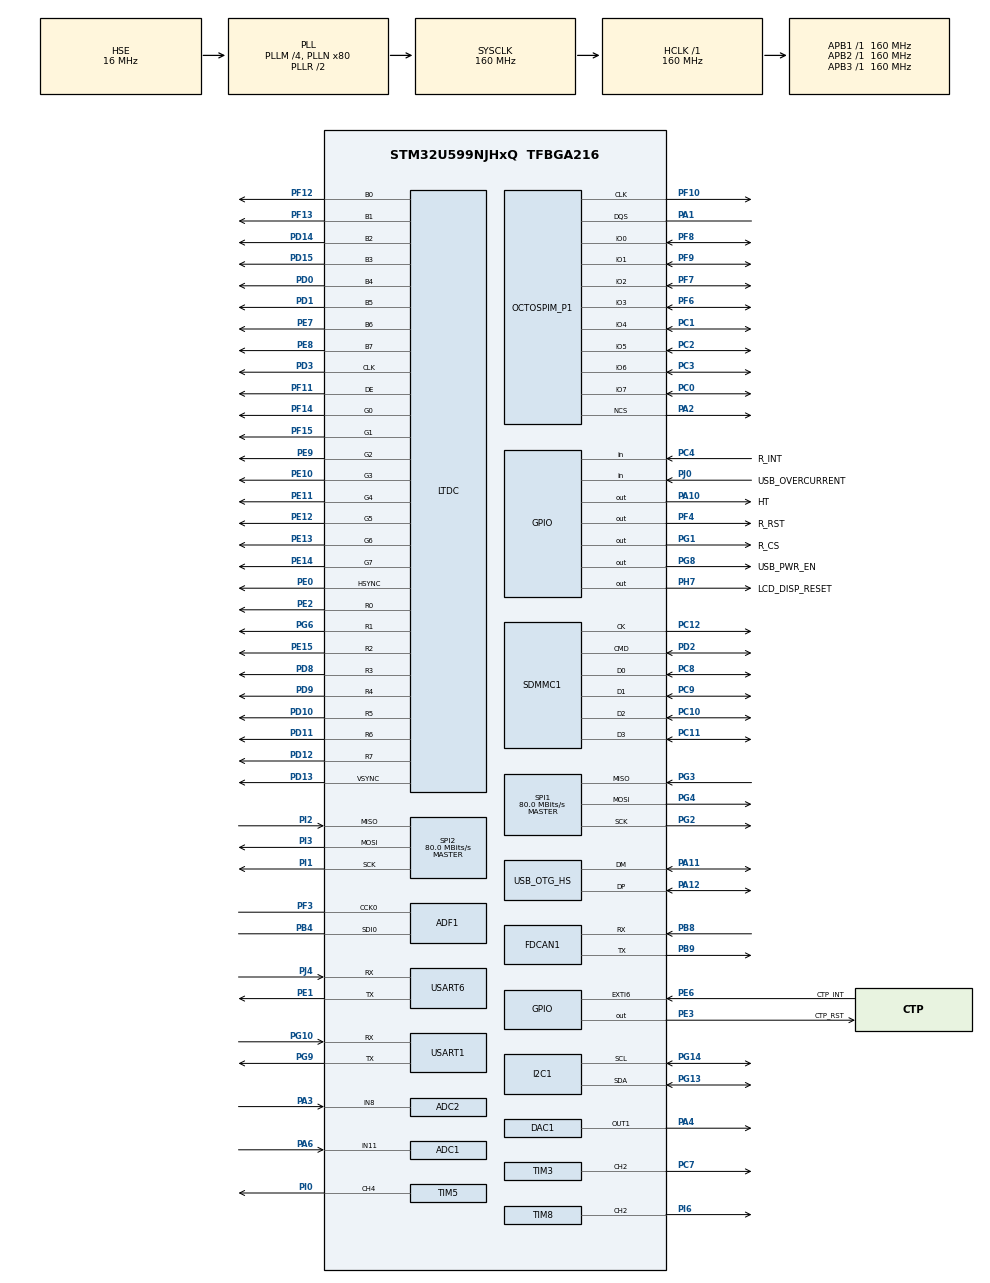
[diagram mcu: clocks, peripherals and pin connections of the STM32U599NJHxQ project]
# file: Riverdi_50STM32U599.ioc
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ADC1.Channel-0\#ChannelRegularConversion=ADC_CHANNEL_11
ADC1.ClockPrescaler=ADC_CLOCK_ASYNC_DIV4
ADC1.ContinuousConvMode=ENABLE
ADC1.ConversionDataManagement=ADC_CONVERSIONDATA_DMA_CIRCULAR
ADC1.DMAContinuousRequests=ENABLE
ADC1.DataAlign=ADC_DATAALIGN_LEFT
ADC1.MonitoredBy-0\#ChannelRegularConversion=__NULL
ADC1.NbrOfConversionFlag=1
ADC1.OffsetNumber-0\#ChannelRegularConversion=ADC_OFFSET_NONE
ADC1.Rank-0\#ChannelRegularConversion=1
ADC1.SamplingTime-0\#ChannelRegularConversion=ADC_SAMPLETIME_5CYCLE
ADC1.master=1
ADC2.Channel-0\#ChannelRegularConversion=ADC_CHANNEL_8
ADC2.ClockPrescaler=ADC_CLOCK_ASYNC_DIV4
ADC2.ContinuousConvMode=ENABLE
ADC2.ConversionDataManagement=ADC_CONVERSIONDATA_DMA_CIRCULAR
ADC2.DMAContinuousRequests=ENABLE
ADC2.DataAlign=ADC_DATAALIGN_RIGHT
ADC2.MonitoredBy-0\#ChannelRegularConversion=__NULL
ADC2.NbrOfConversionFlag=1
ADC2.OffsetNumber-0\#ChannelRegularConversion=ADC_OFFSET_NONE
ADC2.Rank-0\#ChannelRegularConversion=1
ADC2.SamplingTime-0\#ChannelRegularConversion=ADC_SAMPLETIME_5CYCLE
ADC2.TriggerFrequencyMode=ADC_TRIGGER_FREQ_LOW
CORTEX_M33_NS.userName=CORTEX_M33
DAC1.DAC_Channel-DAC_OUT1=DAC_CHANNEL_1
DAC1.DAC_OutputBuffer_OUT1-DAC_OUT1=DAC_OUTPUTBUFFER_ENABLE
DAC1.DAC_SignedFormat-DAC_OUT1=ENABLE
DAC1.DAC_Trigger-DAC_OUT1=DAC_TRIGGER_T1_TRGO
DAC1.WaveGeneration-DAC_OUT1=DISABLE
FDCAN1.CalculateBaudRateNominal=3333333
FDCAN1.CalculateTimeBitNominal=300
FDCAN1.CalculateTimeQuantumNominal=100.0
FDCAN1.FrameFormat=FDCAN_FRAME_FD_BRS
FILEX.FILEX_APPLICATION_THREAD_STACK_SIZE=4096
FILEX.FX_APP_MEM_POOL_SIZE=64*1024
FILEX.FX_DRIVER_SDMMC_INIT=1
FILEX.FX_DRIVER_USE_64BIT_LBA=0
FILEX.FX_ENABLE_EXFAT=1
FILEX.FX_EXFAT_MAX_CACHE_SIZE_NB_BIT=9
FILEX.FX_FAT_MAP_SIZE=256
FILEX.FX_FAULT_TOLERANT_CACHE_SIZE_NB_SIZE=9
FILEX.FX_MEDIA_STATISTICS_DISABLE=0
FILEX.FX_SD_INTERFACE=1
FILEX.FX_UPDATE_RATE_IN_SECONDS=1
FILEX.MAX_FAT_CACHE_NB_BIT=4
FILEX.MAX_SECTOR_CACHE_NB_BIT=4
FILEX.useRTOS=1
GPDMA1.CIRCULARMODE_GPDMACH0=ENABLE
GPDMA1.CIRCULARMODE_GPDMACH1=ENABLE
GPDMA1.CIRCULARMODE_GPDMACH2=ENABLE
GPDMA1.DATAHANDLING_GPDMACH1=NONE
GPDMA1.DATAHANDLING_GPDMACH2=NONE
GPDMA1.DESTDATAWIDTH_GPDMACH0=DMA_DEST_DATAWIDTH_HALFWORD
GPDMA1.DESTDATAWIDTH_GPDMACH1=DMA_DEST_DATAWIDTH_HALFWORD
GPDMA1.DESTDATAWIDTH_GPDMACH2=DMA_DEST_DATAWIDTH_HALFWORD
GPDMA1.DESTINC_GPDMACH1=DMA_DINC_INCREMENTED
GPDMA1.DIRECTION_GPDMACH2=DMA_MEMORY_TO_PERIPH
GPDMA1.IPHANDLE_GPDMACH0-SIMPLEREQUEST_GPDMACH0=__NULL
GPDMA1.IPHANDLE_GPDMACH1-SIMPLEREQUEST_GPDMACH1=__NULL
GPDMA1.IPHANDLE_GPDMACH2-SIMPLEREQUEST_GPDMACH2=__NULL
GPDMA1.REQUEST_GPDMACH0=GPDMA1_REQUEST_ADC1
GPDMA1.REQUEST_GPDMACH1=GPDMA1_REQUEST_ADC2
GPDMA1.REQUEST_GPDMACH2=GPDMA1_REQUEST_DAC1_CH1
GPDMA1.SRCDATAWIDTH_GPDMACH0=DMA_SRC_DATAWIDTH_HALFWORD
GPDMA1.SRCDATAWIDTH_GPDMACH1=DMA_SRC_DATAWIDTH_HALFWORD
GPDMA1.SRCDATAWIDTH_GPDMACH2=DMA_SRC_DATAWIDTH_HALFWORD
GPDMA1.SRCINC_GPDMACH2=DMA_SINC_INCREMENTED
GPDMA1.TRIGGERPOLARITY_GPDMACH1=DMA_TRIG_POLARITY_MASKED
I2C1.Timing=0x30909DEC
LTDC.ActiveW=800
LTDC.Alpha_L0=255
LTDC.FBStartAdress_L0=0x20156C00
LTDC.HBP=8
LTDC.HFP=8
LTDC.HSync=4
LTDC.ImageHeight_L0=480
LTDC.ImageWidth_L0=800
LTDC.Layers=0
LTDC.PixelFormat_L0=LTDC_PIXEL_FORMAT_RGB888
LTDC.VBP=8
LTDC.VFP=8
LTDC.WindowX1_L0=800
LTDC.WindowY1_L0=480
Mcu.Family=STM32U5
Mcu.Name=STM32U599NJHxQ
Mcu.Package=TFBGA216
NVIC.ADC1_2_IRQn=true\:0\:0\:false\:false\:true\:false\:true\:true\:true
NVIC.DAC1_IRQn=true\:0\:0\:false\:false\:true\:false\:true\:true\:true
NVIC.EXTI6_IRQn=true\:0\:0\:false\:false\:true\:false\:true\:true\:true
NVIC.GPDMA1_Channel0_IRQn=true\:0\:0\:false\:false\:true\:true\:false\:true\:true
NVIC.GPDMA1_Channel1_IRQn=true\:0\:0\:false\:false\:true\:true\:false\:true\:true
NVIC.GPDMA1_Channel2_IRQn=true\:0\:0\:false\:false\:true\:true\:false\:true\:true
NVIC.GPU2D_ER_IRQn=true\:0\:0\:false\:false\:true\:false\:false\:true\:true
NVIC.GPU2D_IRQn=true\:0\:0\:false\:false\:true\:false\:false\:true\:true
NVIC.LTDC_IRQn=true\:0\:0\:false\:false\:true\:false\:true\:true\:true
NVIC.OTG_HS_IRQn=true\:6\:0\:true\:false\:true\:false\:true\:true\:true
NVIC.PriorityGroup=NVIC_PRIORITYGROUP_4
NVIC.SDMMC1_IRQn=true\:0\:0\:false\:false\:true\:false\:true\:true\:true
NVIC.TIM2_IRQn=true\:15\:0\:false\:false\:true\:false\:false\:true\:true
NVIC.TimeBase=TIM2_IRQn
NVIC.TimeBaseIP=TIM2
OCTOSPI1.ChipSelectHighTime=2
OCTOSPI1.ClockPrescaler=2
OCTOSPI1.DelayHoldQuarterCycle=HAL_OSPI_DHQC_ENABLE
OCTOSPI1.FifoThreshold=4
OCTOSPI1.MemoryType=HAL_OSPI_MEMTYPE_MACRONIX
PA0.Signal=USART2_CTS
PA1.Mode=OCTOSPI1_Port1_DQS
PA1.Signal=OCTOSPIM_P1_DQS
PA10.GPIO_Label=HT
PA10.Signal=GPIO_Output
PA11.Mode=Internal_Phy_Host
PA11.Signal=USB_OTG_HS_DM
PA12.Mode=Internal_Phy_Host
PA12.Signal=USB_OTG_HS_DP
PA13\ (JTMS/SWDIO).Mode=Trace_Asynchronous_SW
PA13\ (JTMS/SWDIO).Signal=DEBUG_JTMS-SWDIO
PA14\ (JTCK/SWCLK).Mode=Trace_Asynchronous_SW
PA14\ (JTCK/SWCLK).Signal=DEBUG_JTCK-SWCLK
PA2.Mode=OCTOSPI1_Port1_NCS
PA2.Signal=OCTOSPIM_P1_NCS
PA3.Mode=IN8-Single-Ended
PA3.Signal=ADC2_IN8
PA4.Signal=COMP_DAC11_group
PA6.Mode=IN11-Single-Ended
PA6.Signal=ADC1_IN11
PB11.GPIO_Speed=GPIO_SPEED_FREQ_VERY_HIGH
PB11.Signal=I2C4_SDA
PB3\ (JTDO/TRACESWO).Mode=Trace_Asynchronous_SW
PB3\ (JTDO/TRACESWO).Signal=DEBUG_JTDO-SWO
PB4\ (NJTRST).Mode=MOD_ADF_CCK
PB4\ (NJTRST).Signal=ADF1_SDI0
PB8.GPIO_Speed=GPIO_SPEED_FREQ_VERY_HIGH
PB8.Mode=FDCAN_Activate
PB8.Signal=FDCAN1_RX
PB9.GPIO_Speed=GPIO_SPEED_FREQ_VERY_HIGH
PB9.Mode=FDCAN_Activate
PB9.Signal=FDCAN1_TX
PC0.Mode=OCTOSPI1_IOH_Port1H
PC0.Signal=OCTOSPIM_P1_IO7
PC1.Mode=OCTOSPI1_IOH_Port1H
PC1.Signal=OCTOSPIM_P1_IO4
PC10.GPIO_Speed_High_Only=GPIO_SPEED_FREQ_VERY_HIGH
PC10.Mode=SD_4_bits_Wide_bus
PC10.Signal=SDMMC1_D2
PC11.GPIO_Speed_High_Only=GPIO_SPEED_FREQ_VERY_HIGH
PC11.Mode=SD_4_bits_Wide_bus
PC11.Signal=SDMMC1_D3
PC12.GPIO_Speed_High_Only=GPIO_SPEED_FREQ_VERY_HIGH
PC12.Mode=SD_4_bits_Wide_bus
PC12.Signal=SDMMC1_CK
PC13.Signal=RTC_OUT1
PC14-OSC32_IN\ (PC14).Mode=LSE-External-Oscillator
PC14-OSC32_IN\ (PC14).Signal=RCC_OSC32_IN
PC15-OSC32_OUT\ (PC15).Mode=LSE-External-Oscillator
PC15-OSC32_OUT\ (PC15).Signal=RCC_OSC32_OUT
PC2.Mode=OCTOSPI1_IOH_Port1H
PC2.Signal=OCTOSPIM_P1_IO5
PC3.Mode=OCTOSPI1_IOH_Port1H
PC3.Signal=OCTOSPIM_P1_IO6
PC4.GPIO_Label=R_INT
PC4.Signal=GPIO_Input
PC5.Signal=USART3_RX
PC7.Signal=S_TIM3_CH2
PC8.GPIO_Speed_High_Only=GPIO_SPEED_FREQ_VERY_HIGH
PC8.Mode=SD_4_bits_Wide_bus
PC8.Signal=SDMMC1_D0
PC9.GPIO_Speed_High_Only=GPIO_SPEED_FREQ_VERY_HIGH
PC9.Mode=SD_4_bits_Wide_bus
PC9.Signal=SDMMC1_D1
PD0.GPIO_Speed=GPIO_SPEED_FREQ_VERY_HIGH
PD0.Mode=RGB888
PD0.Signal=LTDC_B4
PD1.GPIO_Speed=GPIO_SPEED_FREQ_VERY_HIGH
PD1.Mode=RGB888
PD1.Signal=LTDC_B5
PD10.GPIO_Speed=GPIO_SPEED_FREQ_VERY_HIGH
PD10.Mode=RGB888
PD10.Signal=LTDC_R5
PD11.GPIO_Speed=GPIO_SPEED_FREQ_VERY_HIGH
PD11.Mode=RGB888
PD11.Signal=LTDC_R6
PD12.GPIO_Speed=GPIO_SPEED_FREQ_VERY_HIGH
PD12.Mode=RGB888
PD12.Signal=LTDC_R7
PD13.GPIO_Speed=GPIO_SPEED_FREQ_VERY_HIGH
PD13.Mode=RGB888
PD13.Signal=LTDC_VSYNC
PD14.GPIO_Speed=GPIO_SPEED_FREQ_VERY_HIGH
PD14.Mode=RGB888
PD14.Signal=LTDC_B2
PD15.GPIO_Speed=GPIO_SPEED_FREQ_VERY_HIGH
PD15.Mode=RGB888
PD15.Signal=LTDC_B3
PD2.GPIO_Speed_High_Only=GPIO_SPEED_FREQ_VERY_HIGH
PD2.Mode=SD_4_bits_Wide_bus
PD2.Signal=SDMMC1_CMD
PD3.GPIO_Speed=GPIO_SPEED_FREQ_VERY_HIGH
PD3.Mode=RGB888
PD3.Signal=LTDC_CLK
PD4.Signal=USART2_RTS
PD5.Signal=USART2_TX
PD8.GPIO_Speed=GPIO_SPEED_FREQ_VERY_HIGH
PD8.Mode=RGB888
PD8.Signal=LTDC_R3
PD9.GPIO_Speed=GPIO_SPEED_FREQ_VERY_HIGH
PD9.Mode=RGB888
PD9.Signal=LTDC_R4
PE0.GPIO_Speed=GPIO_SPEED_FREQ_VERY_HIGH
PE0.Mode=RGB888
PE0.Signal=LTDC_HSYNC
PE1.Mode=Asynchronous
PE1.Signal=USART6_TX
PE10.GPIO_Speed=GPIO_SPEED_FREQ_VERY_HIGH
PE10.Mode=RGB888
PE10.Signal=LTDC_G3
PE11.GPIO_Speed=GPIO_SPEED_FREQ_VERY_HIGH
PE11.Mode=RGB888
PE11.Signal=LTDC_G4
PE12.GPIO_Speed=GPIO_SPEED_FREQ_VERY_HIGH
PE12.Mode=RGB888
PE12.Signal=LTDC_G5
PE13.GPIO_Speed=GPIO_SPEED_FREQ_VERY_HIGH
PE13.Mode=RGB888
PE13.Signal=LTDC_G6
PE14.GPIO_Speed=GPIO_SPEED_FREQ_VERY_HIGH
PE14.Mode=RGB888
PE14.Signal=LTDC_G7
PE15.GPIO_Speed=GPIO_SPEED_FREQ_VERY_HIGH
PE15.Mode=RGB888
PE15.Signal=LTDC_R2
PE2.GPIO_Speed=GPIO_SPEED_FREQ_VERY_HIGH
PE2.Mode=RGB888
PE2.Signal=LTDC_R0
PE3.GPIO_Label=CTP_RST
PE3.GPIO_PuPd=GPIO_PULLDOWN
PE3.Signal=GPIO_Output
PE6.GPIO_Label=CTP_INT
PE6.GPIO_ModeDefaultEXTI=GPIO_MODE_IT_FALLING
PE6.GPIO_PuPd=GPIO_PULLUP
PE6.Signal=GPXTI6
PE7.GPIO_Speed=GPIO_SPEED_FREQ_VERY_HIGH
PE7.Mode=RGB888
PE7.Signal=LTDC_B6
PE8.GPIO_Speed=GPIO_SPEED_FREQ_VERY_HIGH
PE8.Mode=RGB888
PE8.Signal=LTDC_B7
PE9.GPIO_Speed=GPIO_SPEED_FREQ_VERY_HIGH
PE9.Mode=RGB888
PE9.Signal=LTDC_G2
PF10.Mode=O1_P1_CLK
PF10.Signal=OCTOSPIM_P1_CLK
PF11.GPIO_Speed=GPIO_SPEED_FREQ_VERY_HIGH
PF11.Mode=RGB888
PF11.Signal=LTDC_DE
PF12.GPIO_Speed=GPIO_SPEED_FREQ_VERY_HIGH
PF12.Mode=RGB888
PF12.Signal=LTDC_B0
PF13.GPIO_Speed=GPIO_SPEED_FREQ_VERY_HIGH
PF13.Mode=RGB888
PF13.Signal=LTDC_B1
PF14.GPIO_Speed=GPIO_SPEED_FREQ_VERY_HIGH
PF14.Mode=RGB888
PF14.Signal=LTDC_G0
PF15.GPIO_Speed=GPIO_SPEED_FREQ_VERY_HIGH
PF15.Mode=RGB888
PF15.Signal=LTDC_G1
PF3.Mode=MOD_MDF_CCK0
PF3.Signal=ADF1_CCK0
PF4.GPIO_Label=R_RST
PF4.GPIO_PuPd=GPIO_PULLDOWN
PF4.Signal=GPIO_Output
PF6.Mode=OCTOSPI1_IOL_Port1L
PF6.Signal=OCTOSPIM_P1_IO3
PF7.Mode=OCTOSPI1_IOL_Port1L
PF7.Signal=OCTOSPIM_P1_IO2
PF8.Mode=OCTOSPI1_IOL_Port1L
PF8.Signal=OCTOSPIM_P1_IO0
PF9.Mode=OCTOSPI1_IOL_Port1L
PF9.Signal=OCTOSPIM_P1_IO1
PG1.GPIO_Label=R_CS
PG1.Signal=GPIO_Output
PG10.Mode=Asynchronous
PG10.Signal=USART1_RX
PG13.GPIO_Speed=GPIO_SPEED_FREQ_VERY_HIGH
PG13.Mode=I2C
PG13.Signal=I2C1_SDA
PG14.GPIO_Speed=GPIO_SPEED_FREQ_VERY_HIGH
PG14.Mode=I2C
PG14.Signal=I2C1_SCL
PG2.GPIO_Speed=GPIO_SPEED_FREQ_VERY_HIGH
PG2.Mode=Full_Duplex_Master
PG2.Signal=SPI1_SCK
PG3.GPIO_Speed=GPIO_SPEED_FREQ_VERY_HIGH
PG3.Mode=Full_Duplex_Master
PG3.Signal=SPI1_MISO
PG4.GPIO_Speed=GPIO_SPEED_FREQ_VERY_HIGH
PG4.Mode=Full_Duplex_Master
PG4.Signal=SPI1_MOSI
PG6.GPIO_Speed=GPIO_SPEED_FREQ_VERY_HIGH
PG6.Mode=RGB888
PG6.Signal=LTDC_R1
PG8.GPIO_Label=USB_PWR_EN
PG8.Signal=GPIO_Output
PG9.Mode=Asynchronous
PG9.Signal=USART1_TX
PH0-OSC_IN\ (PH0).Mode=HSE-External-Clock-Source
PH0-OSC_IN\ (PH0).Signal=RCC_OSC_IN
PH7.GPIO_Label=LCD_DISP_RESET
PH7.PinState=GPIO_PIN_RESET
PH7.Signal=GPIO_Output
PI0.Signal=S_TIM5_CH4
PI1.GPIO_Speed=GPIO_SPEED_FREQ_VERY_HIGH
PI1.Mode=Full_Duplex_Master
PI1.Signal=SPI2_SCK
PI2.GPIO_Speed=GPIO_SPEED_FREQ_VERY_HIGH
PI2.Mode=Full_Duplex_Master
PI2.Signal=SPI2_MISO
PI3.GPIO_Speed=GPIO_SPEED_FREQ_VERY_HIGH
PI3.Mode=Full_Duplex_Master
PI3.Signal=SPI2_MOSI
PI6.Signal=S_TIM8_CH2
PJ0.GPIO_Label=USB_OVERCURRENT
PJ0.Signal=GPIO_Input
PJ4.Mode=Asynchronous
PJ4.Signal=USART6_RX
PWR.Mode=PWR_PVD_MODE_NORMAL
PWR.PowerMode=PWR_SMPS_SUPPLY
PWR.pwrPrivilege=PWR_PRIVILEGE_NO
ProjectManager.HeapSize=0xE000
ProjectManager.StackSize=0xE000
ProjectManager.TargetToolchain=STM32CubeIDE
RCC.ADCCLockSelection=RCC_ADCDACCLKSOURCE_MSIK
RCC.ADCFreq_Value=4000000
RCC.AHBFreq_Value=160000000
RCC.APB1Freq_Value=160000000
RCC.APB1TimFreq_Value=160000000
RCC.APB2Freq_Value=160000000
RCC.APB2TimFreq_Value=160000000
RCC.APB3Freq_Value=160000000
RCC.CortexFreq_Value=160000000
RCC.EPOD_VALUE=16000000
RCC.EnableCSSLSE=true
RCC.HCLKFreq_Value=160000000
RCC.HSE_VALUE=16000000
RCC.HSI48_VALUE=48000000
RCC.HSI_VALUE=16000000
RCC.LSIDIV_VALUE=32000
RCC.LTDCCLockSelection=RCC_LTDCCLKSOURCE_PLL3
RCC.MSI_VALUE=4000000
RCC.PLL2M=4
RCC.PLL2R=20
RCC.PLL2Source=RCC_PLLSOURCE_HSE
RCC.PLL3M=4
RCC.PLL3N=75
RCC.PLL3Q=5
RCC.PLL3R=12
RCC.PLL3Source=RCC_PLLSOURCE_HSE
RCC.PLLM=4
RCC.PLLN=80
RCC.PLLSourceVirtual=RCC_PLLSOURCE_HSE
RCC.RTCClockSelection=RCC_RTCCLKSOURCE_LSE
RCC.SYSCLKFreq_VALUE=160000000
RCC.SYSCLKSource=RCC_SYSCLKSOURCE_PLLCLK
RCC.USBPHYCLockSelection=RCC_USBPHYCLKSOURCE_HSE
RCC.VCOOutputFreq_Value=320000000
RCC.rccPrivilegeNSecure=RCC_NSEC_NPRIV
SDMMC1.ClockDiv=8
SDMMC1.HardwareFlowControl=SDMMC_HARDWARE_FLOW_CONTROL_ENABLE
SH.COMP_DAC11_group.0=DAC1_OUT1,DAC_OUT1
SH.S_TIM3_CH2.0=TIM3_CH2,PWM Generation2 CH2
SH.S_TIM5_CH4.0=TIM5_CH4,PWM Generation4 CH4
SH.S_TIM8_CH2.0=TIM8_CH2,Output Compare2 CH2
SPI1.BaudRatePrescaler=SPI_BAUDRATEPRESCALER_2
SPI1.CalculateBaudRate=80.0 MBits/s
SPI1.Direction=SPI_DIRECTION_2LINES
SPI1.Mode=SPI_MODE_MASTER
SPI1.VirtualType=VM_MASTER
SPI2.BaudRatePrescaler=SPI_BAUDRATEPRESCALER_2
SPI2.CalculateBaudRate=80.0 MBits/s
SPI2.Direction=SPI_DIRECTION_2LINES
SPI2.Mode=SPI_MODE_MASTER
SPI2.VirtualType=VM_MASTER
STMicroelectronics.X-CUBE-FREERTOS.1.0.1.configCHECK_FOR_STACK_OVERFLOW=1
STMicroelectronics.X-CUBE-FREERTOS.1.0.1.configTOTAL_HEAP_SIZE=1024*110
STMicroelectronics.X-CUBE-FREERTOS.1.0.1.configUSE_IDLE_HOOK=1
STMicroelectronics.X-CUBE-FREERTOS.1.0.1.configUSE_MALLOC_FAILED_HOOK=1
STMicroelectronics.X-CUBE-TOUCHGFX.4.23.1.ApplicationCcGraphicsJjApplication=TouchGFXOoGenerator
STMicroelectronics.X-CUBE-TOUCHGFX.4.23.1.tgfx_address1=0x20156C00
STMicroelectronics.X-CUBE-TOUCHGFX.4.23.1.tgfx_address2=0x20119400
STMicroelectronics.X-CUBE-TOUCHGFX.4.23.1.tgfx_app_mem_pool_size=32768
STMicroelectronics.X-CUBE-TOUCHGFX.4.23.1.tgfx_app_stack_size=16384
STMicroelectronics.X-CUBE-TOUCHGFX.4.23.1.tgfx_buffering_strategy=Single
STMicroelectronics.X-CUBE-TOUCHGFX.4.23.1.tgfx_display_interface=disp_ltdc
STMicroelectronics.X-CUBE-TOUCHGFX.4.23.1.tgfx_hardware_accelerator=dma_2d
STMicroelectronics.X-CUBE-TOUCHGFX.4.23.1.tgfx_location=By Address
STMicroelectronics.X-CUBE-TOUCHGFX.4.23.1.tgfx_nemap_accelerator=gpu2d_enabled
STMicroelectronics.X-CUBE-TOUCHGFX.4.23.1.tgfx_oswrapper=ThreadX
STMicroelectronics.X-CUBE-TOUCHGFX.4.23.1.tgfx_vector_fonts=Enabled
STMicroelectronics.X-CUBE-TOUCHGFX.4.23.1.tgfx_vector_rendering=Hardware
STMicroelectronics.X-CUBE-TOUCHGFX.4.23.1.tgfx_vsync=vsync_ltdc
STMicroelectronics.X-CUBE-TOUCHGFX.4.23.1_IsPackSelfContextualization=true
THREADX.TX_APP_CREATION=1
THREADX.TX_APP_GENERATE_INIT_CODE=true
THREADX.TX_APP_MEM_POOL_SIZE=256*1024
THREADX.TX_APP_STACK_SIZE=128*1024
THREADX.TX_APP_THREAD_PRIO=30
THREADX.TX_TIMER_THREAD_PRIORITY=0
THREADX.TX_TIMER_TICKS_PER_SECOND=1000
TIM1.PeriodNoDither=7256-1
TIM1.Prescaler=0
TIM1.TIM_MasterOutputTrigger=TIM_TRGO_UPDATE
TIM1.TIM_MasterOutputTrigger2=TIM_TRGO2_UPDATE
TIM1.TIM_MasterSlaveMode=TIM_MASTERSLAVEMODE_ENABLE
TIM15.PeriodNoDither=999
TIM15.Prescaler=4
TIM3.Channel-PWM\ Generation2\ CH2=TIM_CHANNEL_2
TIM5.Channel-PWM\ Generation4\ CH4=TIM_CHANNEL_4
TIM8.Channel-Output\ Compare2\ CH2=TIM_CHANNEL_2
USART1.VirtualMode-Asynchronous=VM_ASYNC
USART6.VirtualMode-Asynchronous=VM_ASYNC
USBX.BSP.number=2
USBX.Core_System=1
USBX.USBX_HOST_APP_THREAD_Size=4*1024
USBX.USBX_HOST_SYS_SIZE=46*1024
USBX.UX_DEBUG_LOG_SIZE=1024
USBX.UX_HOST_APP_MEM_POOL_SIZE=64*1024
USBX.UX_HOST_CLASS_STORAGE_MEMORY_BUFFER_SIZE=8192
USBX.UX_HOST_HNP_POLLING_THREAD_STACK=2048
USBX.UX_Host_Controller=1
USBX.UX_Host_CoreStack=1
USBX.UX_Host_MSC=1
USBX.UX_MAX_CLASS_DRIVER=2
USBX.UX_MAX_DEVICES=1
USBX.UX_MAX_HCD=2
USBX.UX_OTG_SUPPORT-UX_Host_CoreStack_HS=0
USBX.UX_THREAD_STACK_SIZE-UX_Host_CoreStack_HS=2048
USBX0.BSP.STBoard=false
USBX0.BSP.api=Unknown
USBX0.BSP.instance=USB_OTG_HS
USBX0.BSP.ip=USB_OTG_HS
USBX0.BSP.mode=Host_Only
USBX0.BSP.name=USBHost
USBX0.BSP.solution=USB_OTG_HS
USBX1.BSP.STBoard=false
USBX1.BSP.api=Unknown
USBX1.BSP.condition=\!USBPD_USB_SUPPORT
USBX1.BSP.instance=PG8
USBX1.BSP.ip=GPIO
USBX1.BSP.mode=Output
USBX1.BSP.name=Drive_VBUS_HS
USBX1.BSP.solution=PG8
USB_OTG_HS.RefClockSelection=SYSCFG_OTG_HS_PHY_CLK_SELECT_1
USB_OTG_HS.Sof_enable=ENABLE
USB_OTG_HS.VirtualMode=Host_HS
USB_OTG_HS.dma_enable=ENABLE
USB_OTG_HS.speed=HCD_SPEED_HIGH
USB_OTG_HS.use_external_vbus=DISABLE
VP_CORDIC_VS_CORDIC.Mode=CORDIC_Activate
VP_CRC_VS_CRC.Mode=CRC_Activate
VP_DMA2D_VS_DMA2D.Mode=DMA2D_Activate
VP_FILEX_VS_FileOoSystemJjFileXJjCore.Mode=FileX_Core
VP_FILEX_VS_SDOointerface.Mode=SD_interface
VP_GPDMA1_VS_GPDMACH0.Mode=SIMPLEREQUEST_GPDMACH0
VP_GPDMA1_VS_GPDMACH1.Mode=SIMPLEREQUEST_GPDMACH1
VP_GPDMA1_VS_GPDMACH2.Mode=SIMPLEREQUEST_GPDMACH2
VP_GPU2D_VS_GPU2D.Mode=GPU2D_Activate
VP_HASH_VS_HASH.Mode=HASH_Activate
VP_ICACHE_VS_ICACHE.Mode=DirectMappedCache
VP_LPBAMQUEUE_VS_QUEUE.Mode=QUEUEMODE
VP_LPBAM_VS_SIG1.Mode=SmartRun
VP_LPBAM_VS_SIG4.Mode=LPDMA1
VP_MEMORYMAP_VS_MEMORYMAP.Mode=CurAppReg
VP_OCTOSPI1_VS_octo.Mode=octo_mode
VP_PWR_VS_DBSignals.Mode=DisableDeadBatterySignals
VP_PWR_VS_LPOM.Mode=PowerOptimisation
VP_PWR_VS_SECSignals.Mode=Security/Privilege
VP_PWR_V_PVD_IN.Mode=Mode_PVD_Int
VP_PWR_Vdda.Mode=isolationVdda
VP_RNG_VS_RNG.Mode=RNG_Activate
VP_RTC_VS_RTC_Activate.Mode=RTC_Enabled
VP_STMicroelectronics.X-CUBE-TOUCHGFX_VS_GraphicsJjApplication_4.23.1.Mode=GraphicsJjApplication
VP_SYS_VS_tim2.Mode=TIM2
VP_THREADX_VS_RTOSJjThreadXJjCoreJjDefault.Mode=Core_Default
VP_TIM15_VS_ClockSourceINT.Mode=Internal
VP_TIM1_VS_ClockSourceINT.Mode=Internal
VP_TIM6_VS_ClockSourceINT.Mode=Enable_Timer
VP_USBX_Core_System.Mode=Core_System
VP_USBX_UX\ Host\ Controller_HS.Mode=UX_Host_Controller_HS
VP_USBX_UX\ Host\ CoreStack_HS.Mode=UX_Host_CoreStack_HS
VP_USBX_UX\ Host\ MSC_HS.Mode=UX_Host_MSC_HS
board=custom

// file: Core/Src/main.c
/* USER CODE BEGIN Header */
/**
  ******************************************************************************
  * @file           : main.c
  * @brief          : Main program body
  ******************************************************************************
  * @attention
  *
  * Copyright (c) 2023 STMicroelectronics.
  * All rights reserved.
  *
  * This software is licensed under terms that can be found in the LICENSE file
  * in the root directory of this software component.
  * If no LICENSE file comes with this software, it is provided AS-IS.
  *
  ******************************************************************************
  */
/* USER CODE END Header */
#include "app_threadx.h"
#include "main.h"
#include "adc.h"
#include "mdf.h"
#include "cordic.h"
#include "crc.h"
#include "dac.h"
#include "dma2d.h"
#include "fdcan.h"
#include "gpdma.h"
#include "gpu2d.h"
#include "hash.h"
#include "i2c.h"
#include "icache.h"
#include "ltdc.h"
#include "memorymap.h"
#include "octospi.h"
#include "rng.h"
#include "rtc.h"
#include "sdmmc.h"
#include "spi.h"
#include "tim.h"
#include "usart.h"
#include "gpio.h"
#include "app_touchgfx.h"

/* USER CODE BEGIN Includes */
#include "log.h"
#include "fs_bindings.h"
#include "fx_stm32_sd_driver.h"
#include "ux_api.h"
#include "ux_host_class_storage.h"
#include "ux_host_stack.h"
/* USER CODE END Includes */

void SystemClock_Config(void);
static void SystemPower_Config(void);

/* USER CODE BEGIN 0 */
bool ignore_errors = false;
bool error_occurred = false;
/* USER CODE END 0 */

int main(void)
{

  /* USER CODE BEGIN 1 */
#ifdef DEBUG
  log_level(0);
#else
  log_level(1);
#endif
  /* USER CODE END 1 */

  /* MCU Configuration--------------------------------------------------------*/

  /* Reset of all peripherals, Initializes the Flash interface and the Systick. */
  HAL_Init();

  /* Configure the system clock */
  SystemClock_Config();

  /* Configure the System Power */
  SystemPower_Config();

  /* USER CODE BEGIN SysInit */
  log_msg(3, "Initializing HAL...");
  /* USER CODE END SysInit */

  /* Initialize all configured peripherals */
  MX_GPIO_Init();
  MX_GPDMA1_Init();
  MX_ADF1_Init();
  MX_CRC_Init();
  MX_DMA2D_Init();
  MX_FDCAN1_Init();
  MX_GPU2D_Init();
  MX_HASH_Init();
  MX_I2C1_Init();
  MX_ICACHE_Init();
  MX_LTDC_Init();
  MX_OCTOSPI1_Init();
  MX_RNG_Init();
  MX_RTC_Init();
  MX_SDMMC1_SD_Init();
  MX_ADC2_Init();
  MX_CORDIC_Init();
  MX_DAC1_Init();
  MX_SPI1_Init();
  MX_SPI2_Init();
  MX_TIM3_Init();
  MX_TIM5_Init();
  MX_TIM6_Init();
  MX_TIM8_Init();
  MX_TIM15_Init();
  MX_USART1_UART_Init();
  MX_USART6_UART_Init();
  MX_ADC1_Init();
  MX_TIM1_Init();
  /* Call PreOsInit function */
  MX_TouchGFX_PreOSInit();
  /* USER CODE BEGIN 2 */
  if (HAL_TIM_PWM_Start(&htim15, TIM_CHANNEL_1) != HAL_OK)
    {
      /* PWM Generation Error */
      Error_Handler();
    }

  log_msg(3, "Configuring media...");
  fs_register_type(FS_MEDIA_SD, FS_SD_ROOT, fx_stm32_sd_driver);
  fs_register_type(FS_MEDIA_USB, FS_USB_ROOT, _ux_host_class_storage_driver_entry);
  log_msg(3, "Starting RTOS...");
  /* USER CODE END 2 */

  MX_ThreadX_Init();

  /* We should never get here as control is now taken by the scheduler */

  /* Infinite loop */
  while (1)
  {

  }
}

void SystemClock_Config(void)
{
  RCC_OscInitTypeDef RCC_OscInitStruct = {0};
  RCC_ClkInitTypeDef RCC_ClkInitStruct = {0};

  /** Configure the main internal regulator output voltage
  */
  if (HAL_PWREx_ControlVoltageScaling(PWR_REGULATOR_VOLTAGE_SCALE1) != HAL_OK)
  {
    Error_Handler();
  }

  /** Configure LSE Drive Capability
  */
  HAL_PWR_EnableBkUpAccess();
  __HAL_RCC_LSEDRIVE_CONFIG(RCC_LSEDRIVE_LOW);

  /** Initializes the CPU, AHB and APB buses clocks
  */
  RCC_OscInitStruct.OscillatorType = RCC_OSCILLATORTYPE_HSI48|RCC_OSCILLATORTYPE_LSI
                              |RCC_OSCILLATORTYPE_HSE|RCC_OSCILLATORTYPE_LSE
                              |RCC_OSCILLATORTYPE_MSIK;
  RCC_OscInitStruct.HSEState = RCC_HSE_BYPASS;
  RCC_OscInitStruct.LSEState = RCC_LSE_ON;
  RCC_OscInitStruct.HSI48State = RCC_HSI48_ON;
  RCC_OscInitStruct.LSIState = RCC_LSI_ON;
  RCC_OscInitStruct.MSICalibrationValue = RCC_MSICALIBRATION_DEFAULT;
  RCC_OscInitStruct.LSIDiv = RCC_LSI_DIV1;
  RCC_OscInitStruct.MSIKClockRange = RCC_MSIKRANGE_4;
  RCC_OscInitStruct.MSIKState = RCC_MSIK_ON;
  RCC_OscInitStruct.PLL.PLLState = RCC_PLL_ON;
  RCC_OscInitStruct.PLL.PLLSource = RCC_PLLSOURCE_HSE;
  RCC_OscInitStruct.PLL.PLLMBOOST = RCC_PLLMBOOST_DIV1;
  RCC_OscInitStruct.PLL.PLLM = 4;
  RCC_OscInitStruct.PLL.PLLN = 80;
  RCC_OscInitStruct.PLL.PLLP = 2;
  RCC_OscInitStruct.PLL.PLLQ = 2;
  RCC_OscInitStruct.PLL.PLLR = 2;
  RCC_OscInitStruct.PLL.PLLRGE = RCC_PLLVCIRANGE_0;
  RCC_OscInitStruct.PLL.PLLFRACN = 0;
  if (HAL_RCC_OscConfig(&RCC_OscInitStruct) != HAL_OK)
  {
    Error_Handler();
  }

  /** Initializes the CPU, AHB and APB buses clocks
  */
  RCC_ClkInitStruct.ClockType = RCC_CLOCKTYPE_HCLK|RCC_CLOCKTYPE_SYSCLK
                              |RCC_CLOCKTYPE_PCLK1|RCC_CLOCKTYPE_PCLK2
                              |RCC_CLOCKTYPE_PCLK3;
  RCC_ClkInitStruct.SYSCLKSource = RCC_SYSCLKSOURCE_PLLCLK;
  RCC_ClkInitStruct.AHBCLKDivider = RCC_SYSCLK_DIV1;
  RCC_ClkInitStruct.APB1CLKDivider = RCC_HCLK_DIV1;
  RCC_ClkInitStruct.APB2CLKDivider = RCC_HCLK_DIV1;
  RCC_ClkInitStruct.APB3CLKDivider = RCC_HCLK_DIV1;

  if (HAL_RCC_ClockConfig(&RCC_ClkInitStruct, FLASH_LATENCY_4) != HAL_OK)
  {
    Error_Handler();
  }

  /** Enables the Clock Security System
  */
  HAL_RCCEx_EnableLSECSS();
}

/**
  * @brief Power Configuration
  * @retval None
  */
static void SystemPower_Config(void)
{
  HAL_PWREx_EnableVddIO2();

  PWR_PVDTypeDef sConfigPVD = {0};

  /*
   * PVD Configuration
   */
  sConfigPVD.PVDLevel = PWR_PVDLEVEL_0;
  sConfigPVD.Mode = PWR_PVD_MODE_NORMAL;
  HAL_PWR_ConfigPVD(&sConfigPVD);

  /*
   * Enable the PVD Output
   */
  HAL_PWR_EnablePVD();

  /*
   * Disable the internal Pull-Up in Dead Battery pins of UCPD peripheral
   */
  HAL_PWREx_DisableUCPDDeadBattery();

  /*
   * Switch to SMPS regulator instead of LDO
   */
  if (HAL_PWREx_ConfigSupply(PWR_SMPS_SUPPLY) != HAL_OK)
  {
    Error_Handler();
  }
}

void HAL_TIM_PeriodElapsedCallback(TIM_HandleTypeDef *htim)
{
  if (htim->Instance == TIM2) {
    HAL_IncTick();
  }
}

void Error_Handler(void)
{
  /* USER CODE BEGIN Error_Handler_Debug */
  if (ignore_errors)
  {
    error_occurred = true;
    return;
  }
  /* User can add his own implementation to report the HAL error return state */
  __disable_irq();
  while (1)
  {
  }
  /* USER CODE END Error_Handler_Debug */
}
